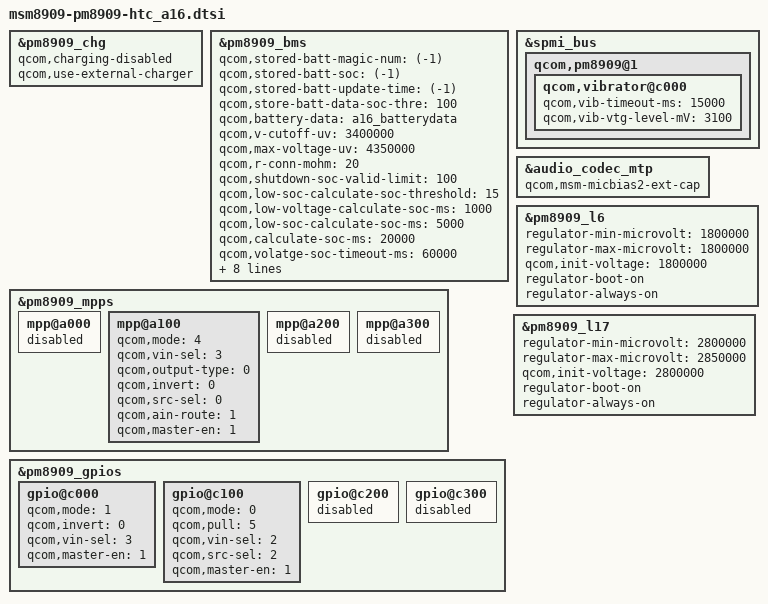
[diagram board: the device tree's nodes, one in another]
/*
 * Copyright (c) 2014, The Linux Foundation. All rights reserved.
 *
 * This program is free software; you can redistribute it and/or modify
 * it under the terms of the GNU General Public License version 2 and
 * only version 2 as published by the Free Software Foundation.
 *
 * This program is distributed in the hope that it will be useful,
 * but WITHOUT ANY WARRANTY; without even the implied warranty of
 * MERCHANTABILITY or FITNESS FOR A PARTICULAR PURPOSE.  See the
 * GNU General Public License for more details.
 */

&pm8909_chg {
	status = "ok";
	qcom,charging-disabled;
	qcom,use-external-charger;
};

&pm8909_bms {
	qcom,stored-batt-magic-num= <(-1)>;
	qcom,stored-batt-soc= <(-1)>;
	qcom,stored-batt-update-time= <(-1)>;
	qcom,store-batt-data-soc-thre = <100>;
	status = "ok";
	qcom,battery-data = <&a16_batterydata>;

	qcom,v-cutoff-uv = <3400000>;
	qcom,max-voltage-uv = <4350000>;
	qcom,r-conn-mohm = <20>;
	qcom,shutdown-soc-valid-limit = <100>;
	qcom,low-soc-calculate-soc-threshold = <15>;
	qcom,low-voltage-calculate-soc-ms = <1000>;
	qcom,low-soc-calculate-soc-ms = <5000>;
	qcom,calculate-soc-ms = <20000>;
	qcom,volatge-soc-timeout-ms = <60000>;
	qcom,low-voltage-threshold = <3450000>;
	qcom,s3-ocv-tolerence-uv = <1200>;
	qcom,low-soc-fifo-length = <2>;
	qcom,force-s3-on-suspend;
	qcom,force-s2-in-charging;
	/*qcom,report-charger-eoc;*/
	qcom,s1-fifo-length = <5>;
	qcom,s2-fifo-length = <5>;
	htc,is-embeded-batt;
};

&spmi_bus {
	qcom,pm8909@1 {
		qcom,vibrator@c000 {
			status = "okay";
			qcom,vib-timeout-ms = <15000>;
			qcom,vib-vtg-level-mV = <3100>;
		};
	};
};

&pm8909_mpps {
	mpp@a000 { /* MPP 1 */
		/* VDD_PX */
		status = "disabled";
	};

	mpp@a100 { /* MPP 2 */
                qcom,mode = <4>; // ANALOG INPUT
                qcom,vin-sel = <3>; // S4 1.8v
		qcom,output-type = <0>; //CMOS
		qcom,invert = <0>; //No Invert
                qcom,src-sel = <0>; //MPP Constant
                qcom,ain-route = <1>; //AMUX6 for MPP 2
                qcom,master-en = <1>; //Enable MPP
	};

	mpp@a200 { /* MPP 3 */
		/* VREF DAC */
		status = "disabled";
	};

	mpp@a300 { /* MPP 4 */
		/* HR LED */
		status = "disabled";
	};
};

&pm8909_gpios {
	gpio@c000 { /* GPIO 1 */
		/* AUDIO_5V_BP_EN */
		qcom,mode = <1>;        /* QPNP_PIN_MODE_DIG_OUT */
		qcom,invert = <0>;      /* NO_Inversion*/
		qcom,vin-sel = <3>;     /* QPNP_PIN_VIN3 */
		qcom,master-en = <1>;
	};

	gpio@c100 { /* GPIO 2 */
		/* NFC_CLK_REQ */
		qcom,mode = <0>; /* QPNP_PIN_MODE_DIG_IN */
		qcom,pull = <5>; /* QPNP_PIN_PULL_NO */
		qcom,vin-sel = <2>; /* QPNP_PIN_VIN2 */
		qcom,src-sel = <2>; /* QPNP_PIN_SEL_FUNC_1 */
		qcom,master-en = <1>;
	};

	gpio@c200 { /* GPIO 3 */
		/* External regulator control for WTR */
		status = "disabled";
	};

	gpio@c300 { /* GPIO 4 */
		/* External regulator control for APC */
		status = "disabled";
	};
};

&audio_codec_mtp {
	qcom,msm-micbias2-ext-cap;
};

&pm8909_l6 {
	status = "okay";
	regulator-min-microvolt = <1800000>;
	regulator-max-microvolt = <1800000>;
	qcom,init-voltage = <1800000>;
	regulator-boot-on;
	regulator-always-on;
};

&pm8909_l17 {
	status = "okay";
	regulator-min-microvolt = <2800000>;
	regulator-max-microvolt = <2850000>;
	qcom,init-voltage = <2800000>;
	regulator-boot-on;
	regulator-always-on;
};

